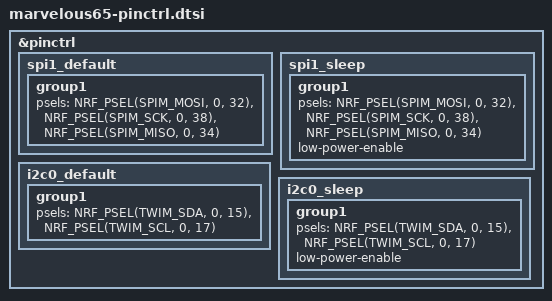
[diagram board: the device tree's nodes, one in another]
/*
 * Copyright (c) 2024 Ujang Karnadi
 *
 * SPDX-License-Identifier: MIT
 *
 * Marvelous65 pinctrl groups.
 *
 * Marvelous65's MCU pinout matches the nrfmicro_13 reference (see
 * https://github.com/joric/nrfmicro), but this is our own board — the
 * pinctrl groups are duplicated here rather than `#include`d from
 * upstream so future pin changes don't require patching the upstream
 * tree.
 */

&pinctrl {
	spi1_default: spi1_default {
		group1 {
			psels = <NRF_PSEL(SPIM_MOSI, 0, 32)>,
				<NRF_PSEL(SPIM_SCK, 0, 38)>,
				<NRF_PSEL(SPIM_MISO, 0, 34)>;
		};
	};

	spi1_sleep: spi1_sleep {
		group1 {
			psels = <NRF_PSEL(SPIM_MOSI, 0, 32)>,
				<NRF_PSEL(SPIM_SCK, 0, 38)>,
				<NRF_PSEL(SPIM_MISO, 0, 34)>;
			low-power-enable;
		};
	};

	i2c0_default: i2c0_default {
		group1 {
			psels = <NRF_PSEL(TWIM_SDA, 0, 15)>,
				<NRF_PSEL(TWIM_SCL, 0, 17)>;
		};
	};

	i2c0_sleep: i2c0_sleep {
		group1 {
			psels = <NRF_PSEL(TWIM_SDA, 0, 15)>,
				<NRF_PSEL(TWIM_SCL, 0, 17)>;
			low-power-enable;
		};
	};
};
